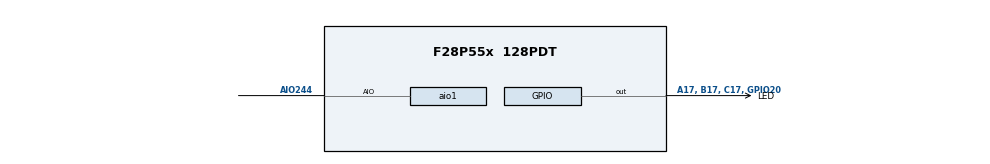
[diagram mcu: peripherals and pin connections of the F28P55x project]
/**
 * @cliArgs --device "F28P55x" --part "F28P55x_128PDT" --package "128PDT" --context "system" --product "C2000WARE@5.05.00.00"
 * @versions {"tool":"1.24.0+4110"}
 */

/**
 * Import the modules used in this configuration.
 */
const aio   = scripting.addModule("/driverlib/aio.js", {}, false);
const aio1  = aio.addInstance();
const gpio  = scripting.addModule("/driverlib/gpio.js", {}, false);
const gpio1 = gpio.addInstance();

/**
 * Write custom configuration values to the imported modules.
 */
aio1.$name                  = "myAIO0";
aio1.aioPin.$assign         = "AIO244";
aio1.aioPin["AIO#"].$assign = "A5, B12, C2, PGA2_INM";

gpio1.$name             = "LED";
gpio1.direction         = "GPIO_DIR_MODE_OUT";
gpio1.writeInitialValue = true;
gpio1.initialValue      = 1;
gpio1.gpioPin.$assign   = "A17, B17, C17, GPIO20";
